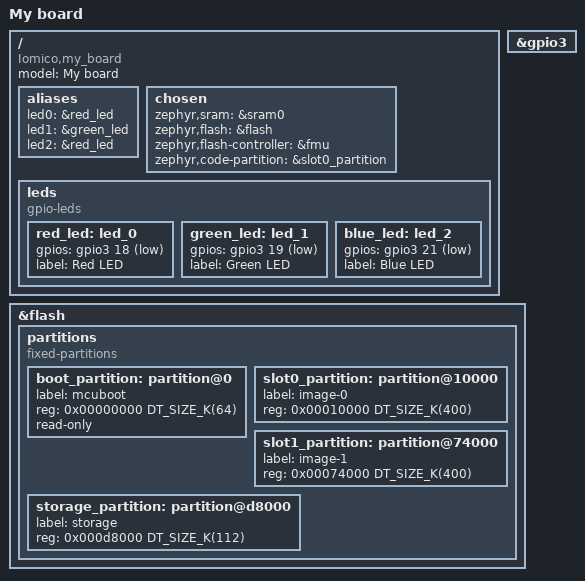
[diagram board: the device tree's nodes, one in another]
/*
 * Copyright 2025 NXP
 *
 * SPDX-License-Identifier: Apache-2.0
 */

/dts-v1/;

#include <nxp/nxp_mcxa276.dtsi>

/ {
	model = "My board";
	compatible = "Iomico,my_board";

	aliases{
		led0 = &red_led;
		led1 = &green_led;
		led2 = &red_led;
	};

	chosen {
		zephyr,sram = &sram0;
		zephyr,flash = &flash;
		zephyr,flash-controller = &fmu;
		zephyr,code-partition = &slot0_partition;
	};

	leds {
		compatible = "gpio-leds";

		red_led: led_0 {
			gpios = <&gpio3 18 GPIO_ACTIVE_LOW>;
			label = "Red LED";
		};

		green_led: led_1 {
			gpios = <&gpio3 19 GPIO_ACTIVE_LOW>;
			label = "Green LED";
		};

		blue_led: led_2 {
			gpios = <&gpio3 21 GPIO_ACTIVE_LOW>;
			label = "Blue LED";
		};
	};

};

&gpio3 {
	status = "okay";
};

&flash {
	partitions {
		compatible = "fixed-partitions";
		#address-cells = <1>;
		#size-cells = <1>;

		boot_partition: partition@0 {
			label = "mcuboot";
			reg = <0x00000000 DT_SIZE_K(64)>;
			read-only;
		};
		slot0_partition: partition@10000 {
			label = "image-0";
			reg = <0x00010000 DT_SIZE_K(400)>;
		};
		slot1_partition: partition@74000 {
			label = "image-1";
			reg = <0x00074000 DT_SIZE_K(400)>;
		};
		storage_partition: partition@d8000 {
			label = "storage";
			reg = <0x000d8000 DT_SIZE_K(112)>;
		};
	};
};

